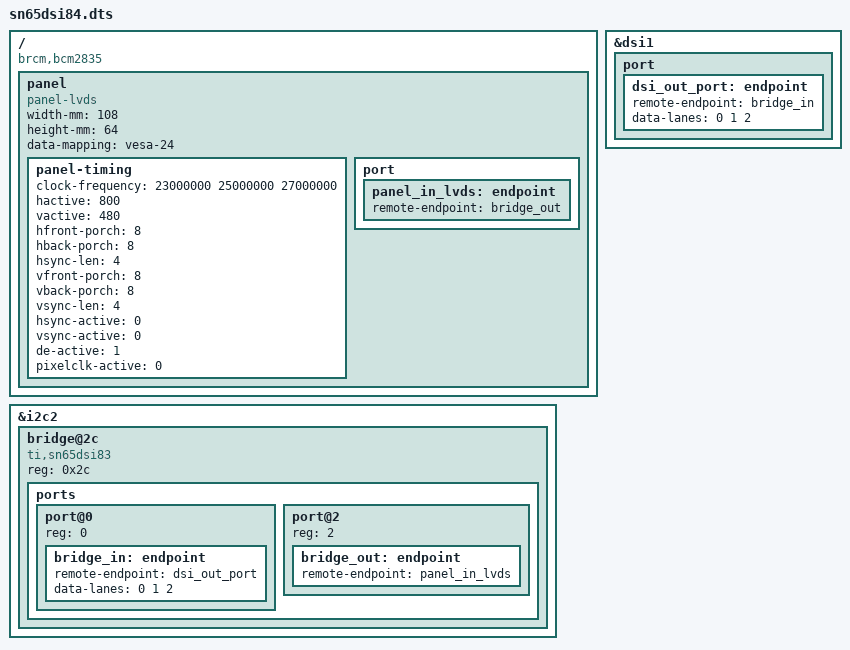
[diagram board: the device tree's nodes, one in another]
/*
 * Derived from:
 * vc4-kms-dsi-ti-sn65dsi84-CSD123IA-01D-overlay.dts
 * aBUGSworsnightmare 20250731
 *
 * Edited for Consolation by Jean-Francois Bilodeau, P.Eng on 2026-11-07
 *
 * Consolation uses SN65DSI84 on DSI1 with up to 4x DSI lanes and 1x 4-lane LVDS output on LVDS_A. 
 * The DSI bridge is controlled through I2C2 on CM5 and doesn't have a dedicated enable input.
 * The display panel is from Riverdi and the part number is RVT50HQLFWN00.
 * The backlight driver is from Texas Instruments TPS61169 and is driven by PWM0_0 on RPI_CMx GPIO12, and doesn't have a dedicated enable input.
 * The schematic can be found on Github --> https://github.com/lecejeff/Consolation
 */

/dts-v1/;
/plugin/;

/ {
	compatible = "brcm,bcm2835";

	fragment@0 {
		target-path = "/";
		__overlay__ {

			panel: panel {
				compatible = "panel-lvds";

				/* Physical dimensions of active area */
				width-mm = <108>;
				height-mm = <64>;

				data-mapping = "vesa-24";

				/* RVT50HQLFWN00 */
				/* 800 x 480 pixels  */
				panel-timing {
					clock-frequency = <23000000 25000000 27000000>;
					hactive = <800>;
					vactive = <480>;
					hfront-porch = <8>;
					hback-porch = <8>;
					hsync-len = <4>;
					vfront-porch = <8>;
					vback-porch = <8>;
					vsync-len = <4>;
					hsync-active = <0>;
					vsync-active = <0>;
					de-active = <1>;
					pixelclk-active = <0>;
				};

				port {
				    panel_in_lvds: endpoint {
				        remote-endpoint = <&bridge_out>;
				    };
				};
			};
		};
	};

	fragment@1 {
		target = <&i2c2>;	
		__overlay__ {
			#gpio-cells = <2>;
			#address-cells = <1>;
			#size-cells = <0>;
			status = "okay";

			/* Information for RVT50HQLFWN00 */
			bridge@2c {
				compatible = "ti,sn65dsi83";
				reg = <0x2c>;	/* 7-bit I2C address when ADDR = 0 */
				ports {
					#address-cells = <1>;
				    	#size-cells = <0>;

			    		port@0 {
						reg = <0>;
						bridge_in: endpoint {
				    			remote-endpoint = <&dsi_out_port>;
				    			// 3-lane DSI is fine here
				    			data-lanes = <0 1 2>;
						};
		    			};

				    	port@2 {
						reg = <2>;
						bridge_out: endpoint {
					    		remote-endpoint = <&panel_in_lvds>;
						};
		    			};
				};
			};
		};
	};

	fragment@2 {
		target = <&dsi1>;
		__overlay__ {
			#address-cells = <1>;
			#size-cells = <0>;
			status = "okay";
			port {
				dsi_out_port: endpoint {
					remote-endpoint = <&bridge_in>;
					data-lanes = <0 1 2>;
				};
			};
		};
	};
};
